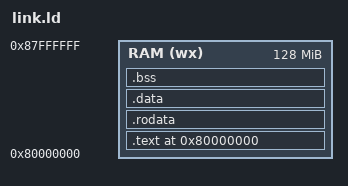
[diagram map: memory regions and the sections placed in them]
OUTPUT_ARCH(riscv)
ENTRY(_start)

MEMORY
{
  RAM (wx) : ORIGIN = 0x80000000, LENGTH = 128M
}

SECTIONS
{
  . = ORIGIN(RAM);

  .text : {
    *(.init)
    *(.text*)
  } > RAM

  .rodata : {
    *(.rodata*)
  } > RAM

  .data : {
    *(.data*)
  } > RAM

  .bss : {
    *(.bss*)
    *(COMMON)
  } > RAM

  . = ALIGN(8);
  PROVIDE(end = .);
}
